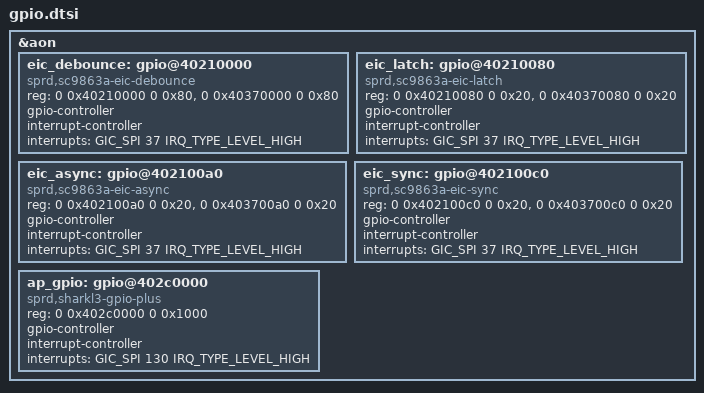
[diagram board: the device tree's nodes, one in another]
// SPDX-License-Identifier: (GPL-2.0+ OR MIT)
/*
 * Unisoc USB dts file
 *
 * Copyright (C) 2020, Unisoc Inc.
 *
 */

&aon {
	eic_debounce: gpio@40210000 {
		compatible = "sprd,sc9863a-eic-debounce", "sprd,sc9860-eic-debounce";
		reg = <0 0x40210000 0 0x80>,
		      <0 0x40370000 0 0x80>;
		gpio-controller;
		#gpio-cells = <2>;
		interrupt-controller;
		#interrupt-cells = <2>;
		interrupts = <GIC_SPI 37 IRQ_TYPE_LEVEL_HIGH>;
	};

	eic_latch: gpio@40210080 {
		compatible = "sprd,sc9863a-eic-latch", "sprd,sc9860-eic-latch";
		reg = <0 0x40210080 0 0x20>,
		      <0 0x40370080 0 0x20>;
		gpio-controller;
		#gpio-cells = <2>;
		interrupt-controller;
		#interrupt-cells = <2>;
		interrupts = <GIC_SPI 37 IRQ_TYPE_LEVEL_HIGH>;
	};

	eic_async: gpio@402100a0 {
		compatible = "sprd,sc9863a-eic-async", "sprd,sc9860-eic-async";
		reg = <0 0x402100a0 0 0x20>,
		      <0 0x403700a0 0 0x20>;
		gpio-controller;
		#gpio-cells = <2>;
		interrupt-controller;
		#interrupt-cells = <2>;
		interrupts = <GIC_SPI 37 IRQ_TYPE_LEVEL_HIGH>;
	};

	eic_sync: gpio@402100c0 {
		compatible = "sprd,sc9863a-eic-sync", "sprd,sc9860-eic-sync";
		reg = <0 0x402100c0 0 0x20>,
		      <0 0x403700c0 0 0x20>;
		gpio-controller;
		#gpio-cells = <2>;
		interrupt-controller;
		#interrupt-cells = <2>;
		interrupts = <GIC_SPI 37 IRQ_TYPE_LEVEL_HIGH>;
	};

	ap_gpio: gpio@402c0000 {
		compatible = "sprd,sharkl3-gpio-plus";
		reg = <0 0x402c0000 0 0x1000>;
		gpio-controller;
		#gpio-cells = <2>;
		interrupt-controller;
		#interrupt-cells = <2>;
		interrupts = <GIC_SPI 130 IRQ_TYPE_LEVEL_HIGH>;
	};

};
